# PIC32MX695F512L register map
Registers are 32-bit, access not given, reset 0x0 unless marked. A register's access mark holds for its fields unless they carry their own. Offsets are from the block's base; [hi:lo] are bit positions; 'fields as' and 'values as' point back to an identical list.

## SPI3 — SPI3 peripheral
Base 0xBF805800
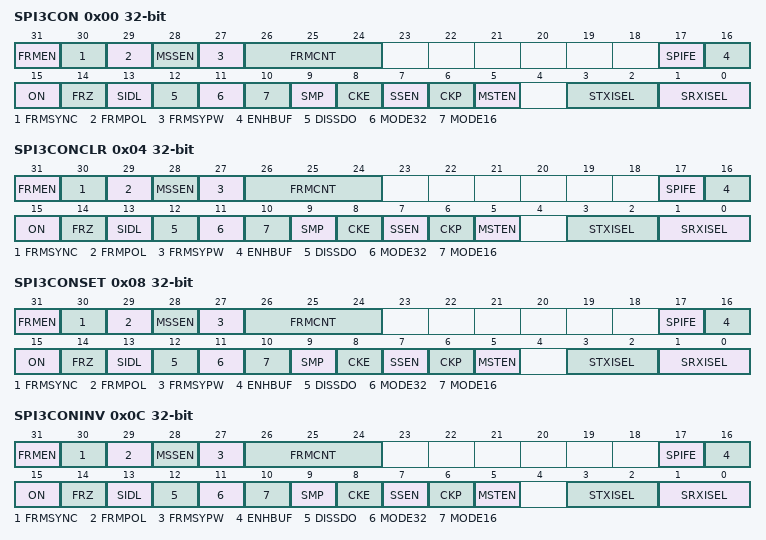
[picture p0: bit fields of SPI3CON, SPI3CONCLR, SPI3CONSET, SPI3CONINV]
0x00 SPI3CON
  [31] FRMEN, [30] FRMSYNC, [29] FRMPOL, [28] MSSEN, [27] FRMSYPW, [26:24] FRMCNT, [17] SPIFE, [16] ENHBUF, [15] ON, [14] FRZ, [13] SIDL, [12] DISSDO, [11] MODE32, [10] MODE16, [9] SMP, [8] CKE, [7] SSEN, [6] CKP, [5] MSTEN, [3:2] STXISEL, [1:0] SRXISEL
0x04 SPI3CONCLR
  fields as SPI3CON
0x08 SPI3CONSET
  fields as SPI3CON
0x0C SPI3CONINV
  fields as SPI3CON
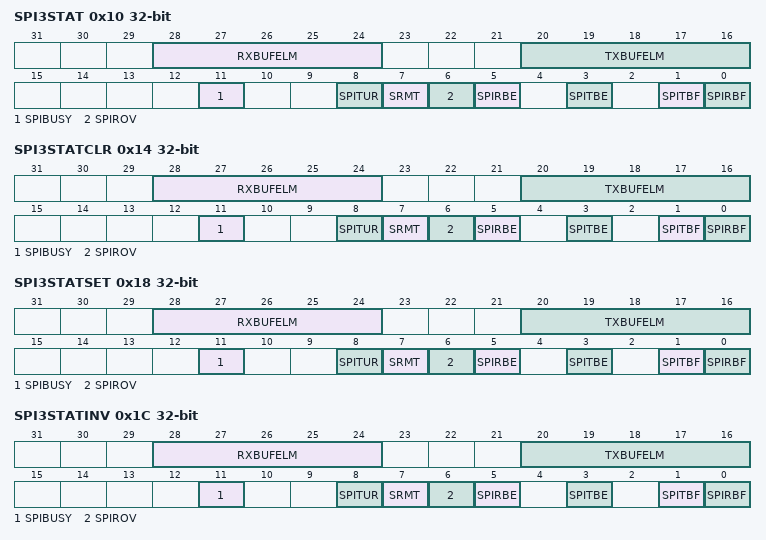
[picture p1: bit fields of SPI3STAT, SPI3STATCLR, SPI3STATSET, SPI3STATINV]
0x10 SPI3STAT
  [28:24] RXBUFELM, [20:16] TXBUFELM, [11] SPIBUSY, [8] SPITUR, [7] SRMT, [6] SPIROV, [5] SPIRBE, [3] SPITBE, [1] SPITBF, [0] SPIRBF
0x14 SPI3STATCLR
  fields as SPI3STAT
0x18 SPI3STATSET
  fields as SPI3STAT
0x1C SPI3STATINV
  fields as SPI3STAT
0x20 SPI3BUF
0x30 SPI3BRG
  [8:0] SPI3BRG
0x34 SPI3BRGCLR
  [8:0] SPI3BRG
0x38 SPI3BRGSET
  [8:0] SPI3BRG
0x3C SPI3BRGINV
  [8:0] SPI3BRG

## SPI2 — SPI2 peripheral
Base 0xBF805A00
Registers as SPI3 (with SPI3 read as SPI2).

## SPI4 — SPI4 peripheral
Base 0xBF805C00
Registers as SPI3 (with SPI3 read as SPI4).

## SPI1 — SPI1 peripheral
Base 0xBF805E00
Registers as SPI3 (with SPI3 read as SPI1).

## UART1 — UART1 peripheral
Base 0xBF806000
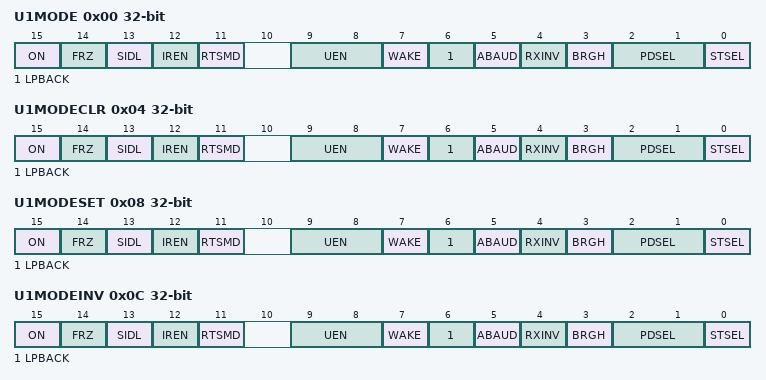
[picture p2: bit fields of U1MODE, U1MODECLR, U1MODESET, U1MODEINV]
0x00 U1MODE
  [15] ON, [14] FRZ, [13] SIDL, [12] IREN, [11] RTSMD, [9:8] UEN, [7] WAKE, [6] LPBACK, [5] ABAUD, [4] RXINV, [3] BRGH, [2:1] PDSEL, [0] STSEL
0x04 U1MODECLR
  fields as U1MODE
0x08 U1MODESET
  fields as U1MODE
0x0C U1MODEINV
  fields as U1MODE
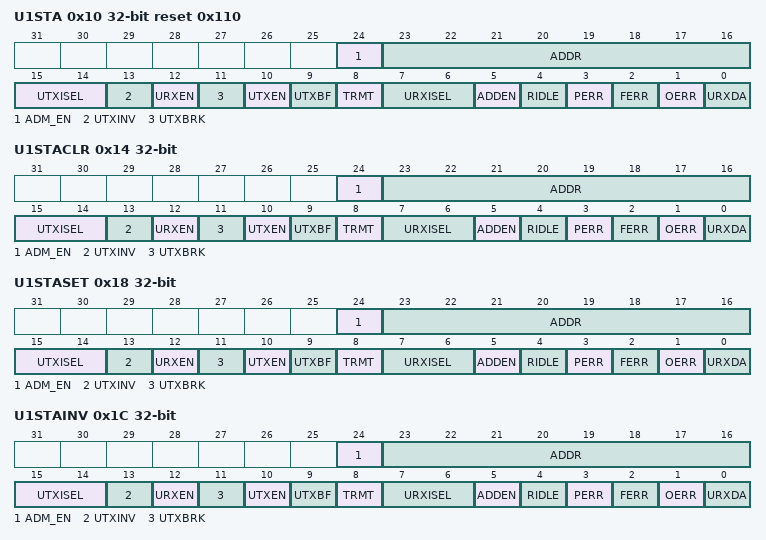
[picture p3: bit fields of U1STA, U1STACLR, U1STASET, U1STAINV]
0x10 U1STA reset 0x110
  [24] ADM_EN, [23:16] ADDR, [15:14] UTXISEL, [13] UTXINV, [12] URXEN, [11] UTXBRK, [10] UTXEN, [9] UTXBF, [8] TRMT, [7:6] URXISEL, [5] ADDEN, [4] RIDLE, [3] PERR, [2] FERR, [1] OERR, [0] URXDA
0x14 U1STACLR
  fields as U1STA
0x18 U1STASET
  fields as U1STA
0x1C U1STAINV
  fields as U1STA
0x20 U1TXREG
  [8:0] U1TXREG
0x30 U1RXREG
  [8:0] U1RXREG
0x40 U1BRG
  [15:0] BRG
0x44 U1BRGCLR
  [15:0] BRG
0x48 U1BRGSET
  [15:0] BRG
0x4C U1BRGINV
  [15:0] BRG

## UART4 — UART4 peripheral
Base 0xBF806200
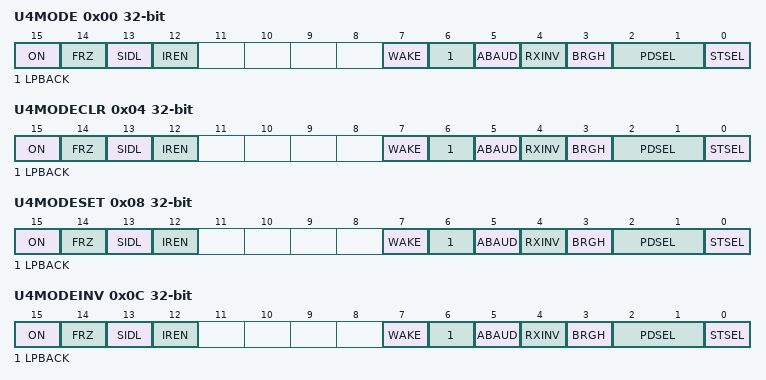
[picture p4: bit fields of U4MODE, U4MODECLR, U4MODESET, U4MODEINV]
0x00 U4MODE
  [15] ON, [14] FRZ, [13] SIDL, [12] IREN, [7] WAKE, [6] LPBACK, [5] ABAUD, [4] RXINV, [3] BRGH, [2:1] PDSEL, [0] STSEL
0x04 U4MODECLR
  fields as U4MODE
0x08 U4MODESET
  fields as U4MODE
0x0C U4MODEINV
  fields as U4MODE
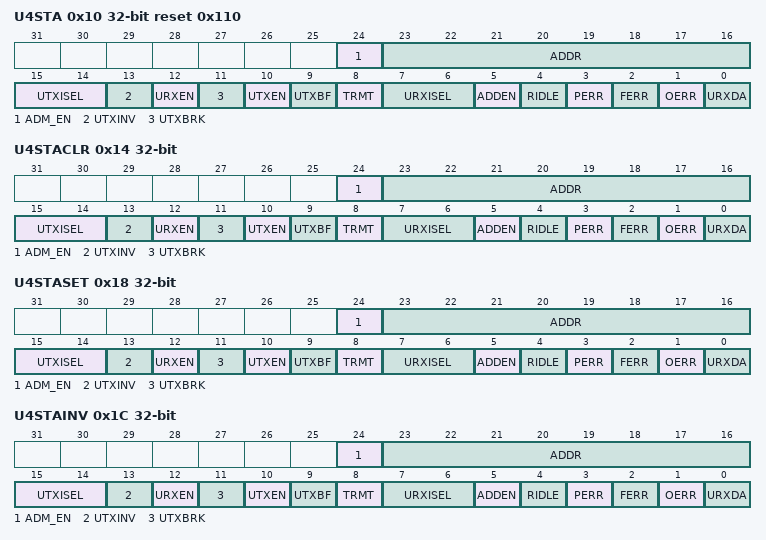
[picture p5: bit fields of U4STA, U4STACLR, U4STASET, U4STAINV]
0x10 U4STA reset 0x110
  [24] ADM_EN, [23:16] ADDR, [15:14] UTXISEL, [13] UTXINV, [12] URXEN, [11] UTXBRK, [10] UTXEN, [9] UTXBF, [8] TRMT, [7:6] URXISEL, [5] ADDEN, [4] RIDLE, [3] PERR, [2] FERR, [1] OERR, [0] URXDA
0x14 U4STACLR
  fields as U4STA
0x18 U4STASET
  fields as U4STA
0x1C U4STAINV
  fields as U4STA
0x20 U4TXREG
  [8:0] U4TXREG
0x30 U4RXREG
  [8:0] U4RXREG
0x40 U4BRG
  [15:0] BRG
0x44 U4BRGCLR
  [15:0] BRG
0x48 U4BRGSET
  [15:0] BRG
0x4C U4BRGINV
  [15:0] BRG

## UART3 — UART3 peripheral
Base 0xBF806400
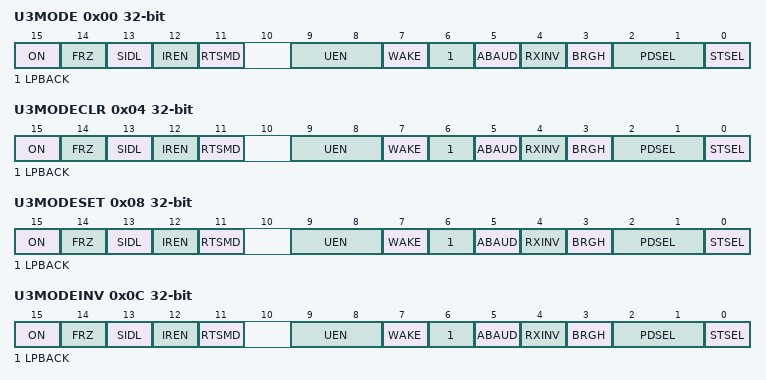
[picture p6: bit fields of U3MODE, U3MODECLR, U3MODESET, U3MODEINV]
0x00 U3MODE
  [15] ON, [14] FRZ, [13] SIDL, [12] IREN, [11] RTSMD, [9:8] UEN, [7] WAKE, [6] LPBACK, [5] ABAUD, [4] RXINV, [3] BRGH, [2:1] PDSEL, [0] STSEL
0x04 U3MODECLR
  fields as U3MODE
0x08 U3MODESET
  fields as U3MODE
0x0C U3MODEINV
  fields as U3MODE
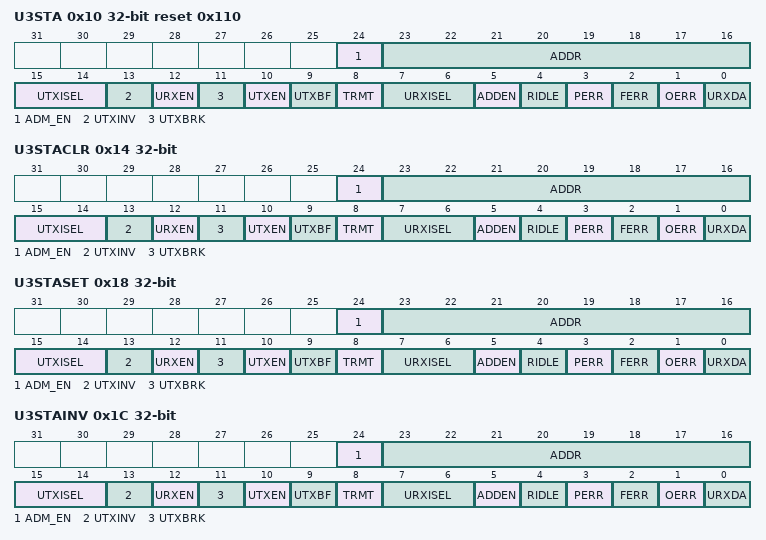
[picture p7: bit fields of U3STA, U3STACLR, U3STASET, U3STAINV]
0x10 U3STA reset 0x110
  [24] ADM_EN, [23:16] ADDR, [15:14] UTXISEL, [13] UTXINV, [12] URXEN, [11] UTXBRK, [10] UTXEN, [9] UTXBF, [8] TRMT, [7:6] URXISEL, [5] ADDEN, [4] RIDLE, [3] PERR, [2] FERR, [1] OERR, [0] URXDA
0x14 U3STACLR
  fields as U3STA
0x18 U3STASET
  fields as U3STA
0x1C U3STAINV
  fields as U3STA
0x20 U3TXREG
  [8:0] U3TXREG
0x30 U3RXREG
  [8:0] U3RXREG
0x40 U3BRG
  [15:0] BRG
0x44 U3BRGCLR
  [15:0] BRG
0x48 U3BRGSET
  [15:0] BRG
0x4C U3BRGINV
  [15:0] BRG

## UART6 — UART6 peripheral
Base 0xBF806600
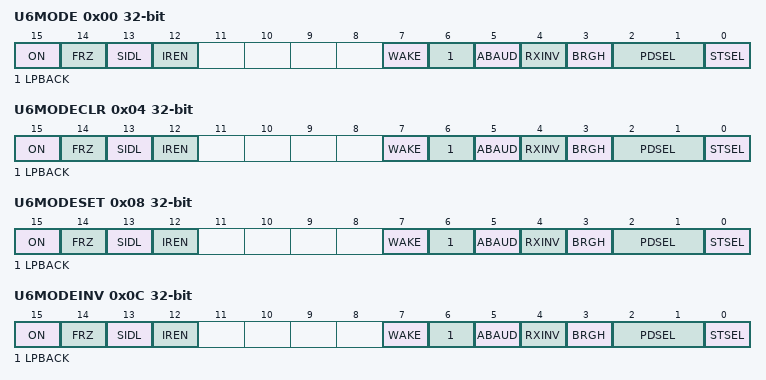
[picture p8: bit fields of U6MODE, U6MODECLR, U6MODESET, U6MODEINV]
0x00 U6MODE
  [15] ON, [14] FRZ, [13] SIDL, [12] IREN, [7] WAKE, [6] LPBACK, [5] ABAUD, [4] RXINV, [3] BRGH, [2:1] PDSEL, [0] STSEL
0x04 U6MODECLR
  fields as U6MODE
0x08 U6MODESET
  fields as U6MODE
0x0C U6MODEINV
  fields as U6MODE
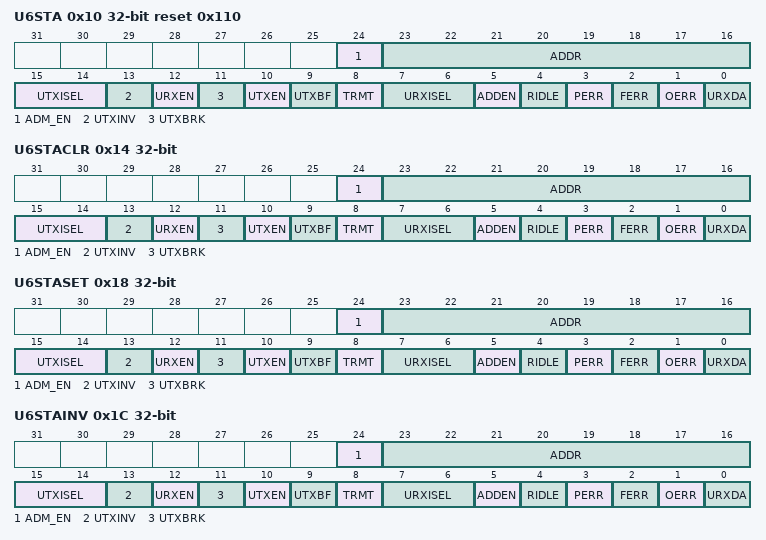
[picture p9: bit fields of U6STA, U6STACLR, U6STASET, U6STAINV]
0x10 U6STA reset 0x110
  [24] ADM_EN, [23:16] ADDR, [15:14] UTXISEL, [13] UTXINV, [12] URXEN, [11] UTXBRK, [10] UTXEN, [9] UTXBF, [8] TRMT, [7:6] URXISEL, [5] ADDEN, [4] RIDLE, [3] PERR, [2] FERR, [1] OERR, [0] URXDA
0x14 U6STACLR
  fields as U6STA
0x18 U6STASET
  fields as U6STA
0x1C U6STAINV
  fields as U6STA
0x20 U6TXREG
  [8:0] U6TXREG
0x30 U6RXREG
  [8:0] U6RXREG
0x40 U6BRG
  [15:0] BRG
0x44 U6BRGCLR
  [15:0] BRG
0x48 U6BRGSET
  [15:0] BRG
0x4C U6BRGINV
  [15:0] BRG
